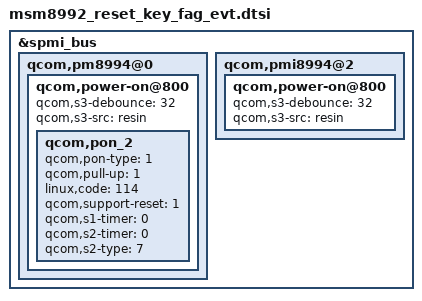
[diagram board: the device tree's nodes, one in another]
&spmi_bus {
        qcom,pm8994@0 {
                qcom,power-on@800 {
                        qcom,s3-debounce = <32>;
                        qcom,s3-src = "resin";
                        qcom,pon_2 {
                                qcom,pon-type = <1>;
                                qcom,pull-up = <1>;
                                linux,code = <114>;
                                qcom,support-reset = <1>;
                                qcom,s1-timer = <0>;
                                qcom,s2-timer = <0>;
                                qcom,s2-type = <7>;

                        };
                };
        };

        qcom,pmi8994@2 {
                qcom,power-on@800 {
                        qcom,s3-debounce = <32>;
                        qcom,s3-src = "resin";
                };
        };

};

